# MK20D5 register map
Vendor: Freescale Semiconductor, Inc.; Series: Kinetis_K; File version: 1.6
CPU: CM4 r0p1, little endian, no MPU, no FPU, VTOR, 4 interrupt priority bits
Registers are 32-bit, read-write, reset 0x0 unless marked. A register's access mark holds for its fields unless they carry their own. Offsets are from the block's base; [hi:lo] are bit positions; {n}, {i} and the like mark numbered series.

## WDOG — Generation 2008 Watchdog Timer
Base 0x40052000; register names take the prefix WDOG_
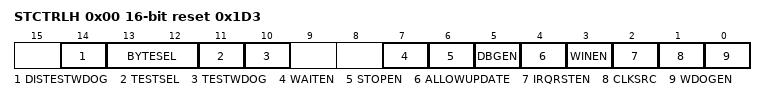
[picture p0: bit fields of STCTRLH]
0x00 STCTRLH 16-bit reset 0x1D3 — Watchdog Status and Control Register High
  [14] DISTESTWDOG — Allows the WDOG's functional test mode to be disabled permanently
    0=WDOG functional test mode is not disabled; 1=WDOG functional test mode is disabled permanently until reset
  [13:12] BYTESEL — This 2-bit field select the byte to be tested when the watchdog is in the byte test mode.
    {v}=Byte {v} selected (v=0..3)
  [11] TESTSEL — Selects the test to be run on the watchdog timer. Effective only if TESTWDOG is set.
    0=Quick test. The timer runs in normal operation. You can load a small time-out value to do a quick test.; 1=Byte test. Puts the timer in the byte test mode where individual bytes of the timer are enabled for operation and are compared for time-out against the corresponding byte of the programmed time-out value. Select the byte through BYTESEL[1:0] for testing.
  [10] TESTWDOG — Puts the watchdog in the functional test mode
  [7] WAITEN — Enables or disables WDOG in wait mode.
    0=WDOG is disabled in CPU wait mode; 1=WDOG is enabled in CPU wait mode
  [6] STOPEN — Enables or disables WDOG in stop mode.
    0=WDOG is disabled in CPU stop mode; 1=WDOG is enabled in CPU stop mode
  [5] DBGEN — Enables or disables WDOG in Debug mode.
    0=WDOG is disabled in CPU Debug mode; 1=WDOG is enabled in CPU Debug mode
  [4] ALLOWUPDATE — Enables updates to watchdog write once registers, after initial configuration window (WCT) closes, through unlock sequence
    0=No further updates allowed to WDOG write once registers; 1=WDOG write once registers can be unlocked for updating
  [3] WINEN — Enable windowing mode.
    0=Windowing mode is disabled; 1=Windowing mode is enabled
  [2] IRQRSTEN — Used to enable the debug breadcrumbs feature
    0=WDOG time-out generates reset only; 1=WDOG time-out initially generates an interrupt. After WCT time, it generates a reset.
  [1] CLKSRC — Selects clock source for the WDOG timer and other internal timing operations.
    0=Dedicated clock source selected as WDOG clock (LPO Oscillator); 1=WDOG clock sourced from alternate clock source
  [0] WDOGEN — Enables or disables the WDOG's operation
    0=WDOG is disabled; 1=WDOG is enabled
0x02 STCTRLL 16-bit reset 0x1 — Watchdog Status and Control Register Low
  [15] INTFLG — Interrupt flag
0x04 TOVALH 16-bit reset 0x4C — Watchdog Time-out Value Register High
  [15:0] TOVALHIGH — Defines the upper 16 bits of the 32-bit time-out value for the watchdog timer
0x06 TOVALL 16-bit reset 0x4B4C — Watchdog Time-out Value Register Low
  [15:0] TOVALLOW — Defines the lower 16 bits of the 32-bit time-out value for the watchdog timer
0x08 WINH 16-bit — Watchdog Window Register High
  [15:0] WINHIGH — Defines the upper 16 bits of the 32-bit window for the windowed mode of operation of the watchdog
0x0A WINL 16-bit reset 0x10 — Watchdog Window Register Low
  [15:0] WINLOW — Defines the lower 16 bits of the 32-bit window for the windowed mode of operation of the watchdog
0x0C REFRESH 16-bit reset 0xB480 — Watchdog Refresh Register
  [15:0] WDOGREFRESH — Watchdog refresh register
0x0E UNLOCK 16-bit reset 0xD928 — Watchdog Unlock Register
  [15:0] WDOGUNLOCK — You can write the unlock sequence values to this register to make the watchdog write once registers writable again
0x10 TMROUTH 16-bit — Watchdog Timer Output Register High
  [15:0] TIMEROUTHIGH — Shows the value of the upper 16 bits of the watchdog timer.
0x12 TMROUTL 16-bit — Watchdog Timer Output Register Low
  [15:0] TIMEROUTLOW — Shows the value of the lower 16 bits of the watchdog timer.
0x14 RSTCNT 16-bit — Watchdog Reset Count Register
  [15:0] RSTCNT — Counts the number of times the watchdog resets the system
0x16 PRESC 16-bit reset 0x400 — Watchdog Prescaler Register
  [10:8] PRESCVAL — 3-bit prescaler for the watchdog clock source
